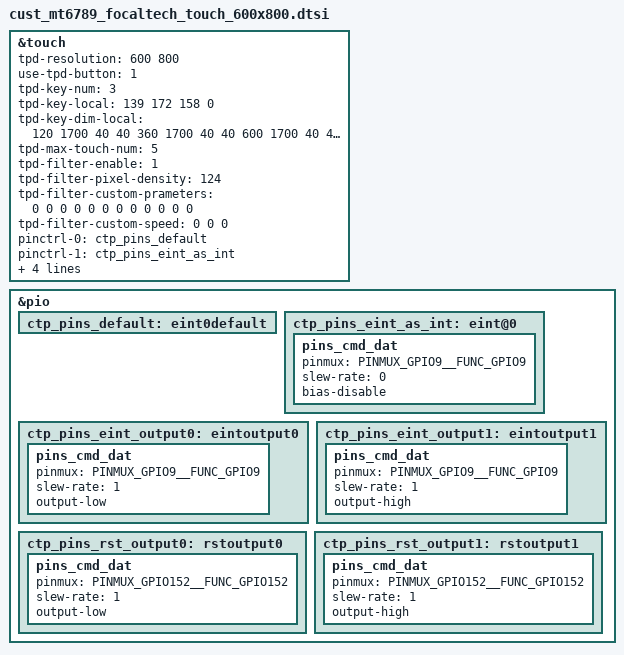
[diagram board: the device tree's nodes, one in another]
// SPDX-License-Identifier: (GPL-2.0 OR MIT)
/*
 * Copyright (C) 2020 MediaTek Inc.
 */
/* TOUCH start */
&touch {
	tpd-resolution = <600 800>;
	use-tpd-button = <1>;
	tpd-key-num = <3>;
	tpd-key-local= <139 172 158 0>;
	tpd-key-dim-local = <120 1700 40 40 360 1700 40 40 600 1700 40 40 0 0 0 0>;
	tpd-max-touch-num = <5>;
	tpd-filter-enable = <1>;
	tpd-filter-pixel-density = <124>;
	tpd-filter-custom-prameters = <0 0 0 0 0 0 0 0 0 0 0 0>;
	tpd-filter-custom-speed = <0 0 0>;
	pinctrl-names = "default", "state_eint_as_int", "state_eint_output0", "state_eint_output1",
		"state_rst_output0", "state_rst_output1";
	pinctrl-0 = <&ctp_pins_default>;
	pinctrl-1 = <&ctp_pins_eint_as_int>;
	pinctrl-2 = <&ctp_pins_eint_output0>;
	pinctrl-3 = <&ctp_pins_eint_output1>;
	pinctrl-4 = <&ctp_pins_rst_output0>;
	pinctrl-5 = <&ctp_pins_rst_output1>;
	status = "okay";
};
&pio {
	ctp_pins_default: eint0default {
	};
	ctp_pins_eint_as_int: eint@0 {
		pins_cmd_dat {
			pinmux = <PINMUX_GPIO9__FUNC_GPIO9>;
			slew-rate = <0>;
			bias-disable;
		};
	};
	ctp_pins_eint_output0: eintoutput0 {
		pins_cmd_dat {
			pinmux = <PINMUX_GPIO9__FUNC_GPIO9>;
			slew-rate = <1>;
			output-low;
		};
	};
	ctp_pins_eint_output1: eintoutput1 {
		pins_cmd_dat {
			pinmux = <PINMUX_GPIO9__FUNC_GPIO9>;
			slew-rate = <1>;
			output-high;
		};
	};
	ctp_pins_rst_output0: rstoutput0 {
		pins_cmd_dat {
			pinmux = <PINMUX_GPIO152__FUNC_GPIO152>;
			slew-rate = <1>;
			output-low;
		};
	};
	ctp_pins_rst_output1: rstoutput1 {
		pins_cmd_dat {
			pinmux = <PINMUX_GPIO152__FUNC_GPIO152>;
			slew-rate = <1>;
			output-high;
		};
	};
};
/* TOUCH end */


/* TOUCH start */
/*
&i2c0 {
		focaltech@38{ 
			compatible = "focaltech,fts";	
			reg = <0x38>;  					
			interrupt-parent = <&pio>;				
			interrupts = <13 0x02>;
            //vdd-supply = <&pm8916_l15>;
            //vcc_i2c-supply = <&pm8916_l16>;
			focaltech,reset-gpio = <pio 12 0x01>; 
			focaltech,irq-gpio = <pio 13 0x02>; 	
			focaltech,max-touch-number = <10>;			
			focaltech,display-coords =  <0 0 1079 1919>;	 
			
			pinctrl-names = "pmx_ts_active","pmx_ts_suspend","pmx_ts_release";
			pinctrl-0 = <&ts_int_active &ts_reset_active>;
			pinctrl-1 = <&ts_int_suspend &ts_reset_suspend>;
			pinctrl-2 = <&ts_release>;

			
			//focaltech,have-key;
			//focaltech,key-number = <3>;	
			//focaltech,keys = <139 102 158>; 	
			//focaltech,key-x-coords = <200 600 800>;
			//focaltech,key-y-coords = <2000 2000 2000>; 
		
};
};
*/

/*
&pio {
	ctp_pins_default: eintdefault {
	};

	ctp_ts_int_active: int_active {
		pins_cmd_dat {
			pinmux = <PINMUX_GPIO9__FUNC_GPIO9>;
			input-enable;
		};
	};
	ctp_ts_reset_active: reset_active {
		pins_cmd_dat {
			pinmux = <PINMUX_GPIO152__FUNC_GPIO152>;
			output-high;
		};
	};
	ctp_ts_int_suspend: int_suspend {
		pins_cmd_dat {
			pinmux = <PINMUX_GPIO9__FUNC_GPIO9>;
			output-low;
		};
	};
	ctp_ts_reset_suspend: reset_suspend {
		pins_cmd_dat {
			pinmux = <PINMUX_GPIO152__FUNC_GPIO152>;
			output-low;
		};
	};
	ctp_ts_i2c_mode: i2cmode_default {
		pins_cmd_dat {
			pinmux = <PINMUX_GPIO130__FUNC_SCL0>,
				<PINMUX_GPIO131__FUNC_SDA0>;
		};
	};
};
*/
/* TOUCH end */

